# LPC43xx register map
File version: 5
Registers are 32-bit, read-write, reset 0x0 unless marked. A register's access mark holds for its fields unless they carry their own. Offsets are from the block's base; [hi:lo] are bit positions; 'fields as' and 'values as' point back to an identical list.

## CREG — Product name title=UM10503 Chapter title=LPC43xx Configuration Registers (CREG) Modification date=10/7/2011 Major revision=0 Minor revision=3
Base 0x40043000
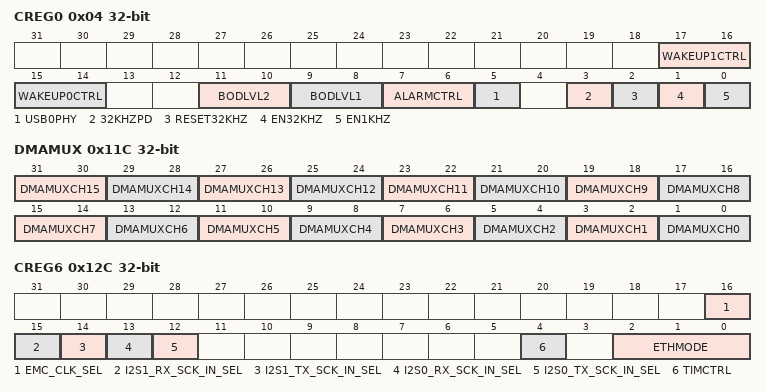
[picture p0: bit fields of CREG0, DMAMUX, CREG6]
0x04 CREG0 reset not defined — Chip configuration register 32 kHz oscillator output and BOD control register.
  [17:16] WAKEUP1CTRL — WAKEUP1 pin input/output control
    0=INPUT_TO_EVENT_ROUTE (Input to event router.); 1=EVENT_ROUTER_EVENT_O (Event router event output.); 3=INPUT_TO_EVENT_ROUTE (Input to event router.)
  [15:14] WAKEUP0CTRL — WAKEUP0 pin input/output control
    values as WAKEUP1CTRL
  [11:10] BODLVL2 — BOD trip level to generate a reset.
    0=1_70_V; 1=1_80_V; 2=1_90_V; 3=2_00_V
  [9:8] BODLVL1 — BOD trip level to generate an interrupt.
    0=2_75_V; 1=2_85_V; 2=2_95_V; 3=3_05_V
  [7:6] ALARMCTRL — RTC_ALARM pin output control
    0=RTC_ALARM_; 1=EVENT_ROUTER_EVENT_; 3=INACTIVE_
  [5] USB0PHY — USB0 PHY power control.
    0=ENABLE_USB0_PHY_POWE (Enable USB0 PHY power.); 1=DISABLE_USB0_PHY_PH (Disable USB0 PHY. PHY powered down.)
  [3] 32KHZPD — 32 kHz power control.
    0=32_KHZ_OSCILLATOR_PO (32 kHz oscillator powered.); 1=32_KHZ_OSCILLATOR_PO (32 kHz oscillator powered-down.)
  [2] RESET32KHZ — 32 kHz oscillator reset
    0=TBD; 1=TBD
  [1] EN32KHZ — Enable 32 kHz output
    0=32_KHZ_OUTPUT_DISABL (32 kHz output disabled.); 1=32_KHZ_OUTPUT_ENABLE (32 kHz output enabled.)
  [0] EN1KHZ — Enable 1 kHz output.
    0=1_KHZ_OUTPUT_DISABLE (1 kHz output disabled.); 1=1_KHZ_OUTPUT_ENABLED
0x100 M4MEMMAP reset 0x10400 — ARM Cortex-M4 memory mapping
  [31:12] M4MAP — Shadow address when accessing memory at address 0x0000 0000
0x118 CREG5 reset not defined — Chip configuration register 5. Controls JTAG access.
  [6] M4TAPSEL
0x11C DMAMUX reset not defined — DMA muxing control
  [31:30] DMAMUXCH15 — Select DMA to peripheral connection for DMA peripheral 15.
    0=DAC; 1=SCT_MATCH_OUTPUT_3; 3=TIMER_3_MATCH_0
  [29:28] DMAMUXCH14 — Select DMA to peripheral connection for DMA peripheral 14.
    0=ADC1; 2=SSP1_TRANSMIT; 3=USART3_TRANSMIT
  [27:26] DMAMUXCH13 — Select DMA to peripheral connection for DMA peripheral 13.
    0=ADC0; 2=SSP1_RECEIVE; 3=USART3_RECEIVE
  [25:24] DMAMUXCH12 — Select DMA to peripheral connection for DMA peripheral 12.
    0=SSP1_TRANSMIT; 2=USART0_RECEIVE
  [23:22] DMAMUXCH11 — Selects DMA to peripheral connection for DMA peripheral 11.
    0=SSP1_RECEIVE; 2=USART0_TRANSMIT
  [21:20] DMAMUXCH10 — Select DMA to peripheral connection for DMA peripheral 10.
    0=SSP0_TRANSMIT; 1=I2S0_CHANNEL_1; 2=SCT_MATCH_OUTPUT_0
  [19:18] DMAMUXCH9 — Select DMA to peripheral connection for DMA peripheral 9.
    0=SSP0_RECEIVE; 1=I2S0_CHANNEL_0; 2=SCT_MATCH_OUTPUT_1
  [17:16] DMAMUXCH8 — Select DMA to peripheral connection for DMA peripheral 8.
    0=TIMER_3_MATCH_1; 1=USART3_RECEIVE; 2=SCT_MATCH_OUTPUT_1
  [15:14] DMAMUXCH7 — Selects DMA to peripheral connection for DMA peripheral 7.
    0=TIMER_3_MATCH_L_0; 1=USART3_TRANSMIT; 2=SCT_MATCH_OUTPUT_0
  [13:12] DMAMUXCH6 — Selects DMA to peripheral connection for DMA peripheral 6.
    0=TIMER_2_MATCH_1; 1=USART2_RECEIVE; 2=SSP1_RECEIVE
  [11:10] DMAMUXCH5 — Select DMA to peripheral connection for DMA peripheral 5.
    0=TIMER_2_MATCH_0; 1=USART2_TRANSMIT; 2=SSP1_TRANSMIT
  [9:8] DMAMUXCH4 — Select DMA to peripheral connection for DMA peripheral 4.
    0=TIMER_1_MATCH_1; 1=UART1_RECEIVE; 2=I2S1_CHANNEL_1; 3=SSP1_RECEIVE
  [7:6] DMAMUXCH3 — Select DMA to peripheral connection for DMA peripheral 3.
    0=TIMER_1_MATCH_0; 1=UART1_TRANSMIT; 2=I2S1_CHANNEL_0; 3=SSP1_TRANSMIT
  [5:4] DMAMUXCH2 — Select DMA to peripheral connection for DMA peripheral 2.
    0=TIMER_0_MATCH_1; 1=USART0_RECEIVE
  [3:2] DMAMUXCH1 — Select DMA to peripheral connection for DMA peripheral 1
    0=TIMER_0_MATCH_0; 1=USART0_TRANSMIT
  [1:0] DMAMUXCH0 — Select DMA to peripheral connection for DMA peripheral 0.
    0=SPIFI; 1=SCT_MATCH_2; 3=T3_MATCH_1
0x128 ETBCFG — ETB RAM configuration
  [0] ETB — Select SRAM interface
    0=ETB_ACCESSES_SRAM_AT (ETB accesses SRAM at address 0x2000 C000.); 1=AHB_ACCESSES_SRAM_AT (AHB accesses SRAM at address 0x2000 C000.)
0x12C CREG6 reset not defined — Chip configuration register 6.
  [16] EMC_CLK_SEL — EMC_CLK divided clock select (see Section 22.1).
    0=EMC_CLK_DIV_NOT_DIVI (EMC_CLK_DIV not divided.); 1=EMC_CLK_DIV_DIVIDED_ (EMC_CLK_DIV divided by 2.)
  [15] I2S1_RX_SCK_IN_SEL — I2S1_RX_SCK input select
    0=I2_S_CLOCK_SELECTED_ (I2 S clock selected as defined by the I2S receive mode register Table 833.); 1=AUDIO_PLL_FOR_I2S_RE (Audio PLL for I2S receive clock MCLK input and MCLK output. The I2S must be configured in slave mode.)
  [14] I2S1_TX_SCK_IN_SEL — I2S1_TX_SCK input select
    0=I2_S_CLOCK_SELECTED_ (I2 S clock selected as defined by the I2S transmit mode register Table 832.); 1=AUDIO_PLL_FOR_I2S_TR (Audio PLL for I2S transmit clock MCLK input and MCLK output. The I2S must be configured in slave mode.)
  [13] I2S0_RX_SCK_IN_SEL — I2S0_RX_SCK input select
    values as I2S1_RX_SCK_IN_SEL
  [12] I2S0_TX_SCK_IN_SEL — I2S0_TX_SCK input select
    values as I2S1_TX_SCK_IN_SEL
  [4] TIMCTRL — Selects the functionality of the SCT outputs.
    0=COMBINE_SCT_TMATCH (Combine SCT and timer match outputs. SCT outputs are ORed with timer outputs.); 1=SCT_ONLY (SCT outputs only. SCT outputs are used without timer match outputs.)
  [2:0] ETHMODE — Selects the Ethernet mode. Reset the ethernet after changing the PHY interface. All other settings are reserved.
    0=MII; 4=RMII
0x130 M4TXEVENT — Cortex-M4 TXEV event clear
  [0] TXEVCLR — Cortex-M4 TXEV event.
    1=NA (Do nothing); 0=CLEAR_TXEV_EVENT_
0x200 CHIPID ro reset not defined — Part ID
  [31:0] ID
0x400 M0TXEVENT — Cortex-M0 TXEV event clear
  [0] TXEVCLR — Cortex-M0 TXEV event.
    1=NA (do nothing); 0=CLEAR_TXEV_EVENT_
0x404 M0APPMEMMAP reset 0x2000 — ARM Cortex-M0 memory mapping
  [31:12] M0APPMAP — Shadow address when accessing memory at address 0x0000 0000
